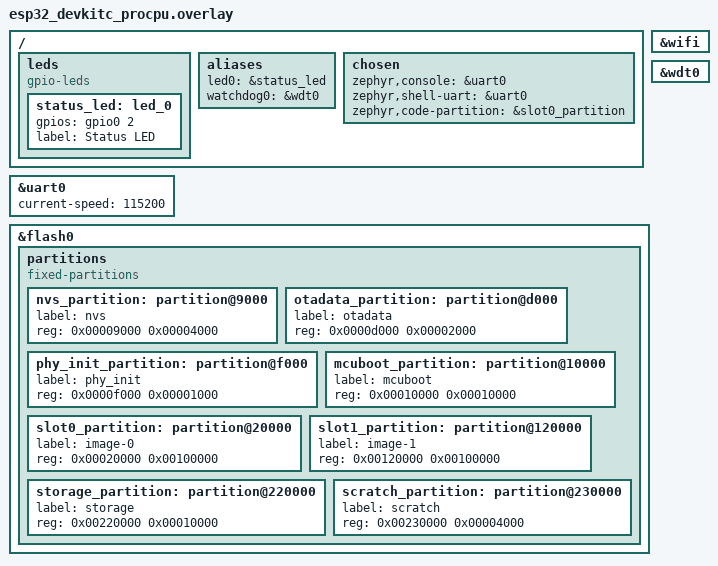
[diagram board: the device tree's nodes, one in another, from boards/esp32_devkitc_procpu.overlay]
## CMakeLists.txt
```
# SPDX-License-Identifier: Apache-2.0

cmake_minimum_required(VERSION 3.20.0)

find_package(Zephyr REQUIRED HINTS $ENV{ZEPHYR_BASE})
project(sample_with_mcuboot)

# Verify that this sample is built through sysbuild to ensure MCUboot is
# automatically included and that sample specific MCUboot configurations are
# used when building MCUboot.
test_sysbuild()

# Fügt Ihre C-Quelldateien zum "app"-Ziel hinzu.
target_sources(app PRIVATE
    src/main.c
    src/blinky.c
    src/wifi_mgmt.c
    src/ota_mgmt.c
    src/utils.c
)

#set(DTC_OVERLAY_FILE ${CMAKE_CURRENT_SOURCE_DIR}/boards/${BOARD}.overlay)

target_include_directories(app PRIVATE 
    include
)

if(CONFIG_RISCV AND CONFIG_SOC_SERIES_ESP32C3)
    target_compile_options(app PRIVATE -march=rv32ima)
    target_link_options(app PRIVATE -march=rv32ima)
endif()
```

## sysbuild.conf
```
SB_CONFIG_BOOTLOADER_MCUBOOT=y
SB_CONFIG_MCUBOOT_MODE_SWAP_USING_MOVE=y
SB_CONFIG_BOOT_SIGNATURE_TYPE_ECDSA_P256=y
SB_CONFIG_BOOT_SIGNATURE_KEY_FILE="C:/Users/SebastianR/Desktop/repos/zephyr-blinky-ota/zephyr-project/keys/ecdsa.pem"

#SB_CONFIG_BOOT_SIGNATURE_TYPE_ED25519=y
#SB_CONFIG_BOOT_SIGNATURE_KEY_FILE="C:/Users/SebastianR/Desktop/repos/zephyr-blinky-ota/zephyr-project/keys/ed25519.pem"

#SB_CONFIG_MCUBOOT_MODE_SWAP_SCRATCH=y
```

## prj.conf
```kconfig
# Empty file
# ======== Logging ========
CONFIG_LOG=y
#CONFIG_LOG_DEFAULT_LEVEL=3

# ======== Shell ========
CONFIG_SHELL=y
CONFIG_SHELL_BACKEND_SERIAL=y

# ======== Basic System and Hardware ========
CONFIG_GPIO=y
CONFIG_WATCHDOG=y
CONFIG_REBOOT=y
CONFIG_MAIN_STACK_SIZE=4096
CONFIG_SYSTEM_WORKQUEUE_STACK_SIZE=2048
CONFIG_HEAP_MEM_POOL_SIZE=65536

# ======== Networking =======
CONFIG_NETWORKING=y
CONFIG_NET_IPV4=y
CONFIG_NET_DHCPV4=y
CONFIG_NET_TCP=y
CONFIG_NET_SOCKETS=y
CONFIG_NET_MGMT=y
CONFIG_NET_MGMT_EVENT=y
CONFIG_NET_BUF_RX_COUNT=16
CONFIG_NET_BUF_TX_COUNT=16

# ======== WiFi ========
CONFIG_WIFI=y
CONFIG_WIFI_ESP32=y
CONFIG_NET_L2_WIFI_MGMT=y
CONFIG_HTTP_CLIENT=y

# ======== JSON Library ========
CONFIG_JSON_LIBRARY=y
# ======== MCUboot & OTA Support for the Application ========

CONFIG_IMG_MANAGER=y
CONFIG_MCUBOOT_IMG_MANAGER=y
CONFIG_IMG_BLOCK_BUF_SIZE=512
#CONFIG_MCUBOOT_SHELL=y # Erlaubt OTA-Befehle über die serielle Konsole
#CONFIG_MCUBOOT_IMGTOOL_SIGN_VERSION="1.0.14+2"

#CONFIG_BOOT_IMAGE_ACCESS_HOOKS=y
# ======== Flash Configuration ========
CONFIG_FLASH=y
CONFIG_FLASH_MAP=y
CONFIG_STREAM_FLASH=y
CONFIG_FLASH_PAGE_LAYOUT=y

# ======== ESP32 Specific Flash Settings ========
CONFIG_ESPTOOLPY_FLASHMODE_QIO=y
CONFIG_ESPTOOLPY_FLASHFREQ_80M=y
CONFIG_ESPTOOLPY_FLASHSIZE_4MB=y

CONFIG_BOOTLOADER_MCUBOOT=y
CONFIG_IMG_BLOCK_BUF_SIZE=1024

CONFIG_GPIO_ESP32=y
CONFIG_PINCTRL=y

# For debugging GPIO issues
CONFIG_GPIO_SHELL=y
CONFIG_DEVICE_SHELL=y
```

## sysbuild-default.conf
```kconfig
SB_CONFIG_BOOT_SIGNATURE_TYPE_ECDSA_P256=y
SB_CONFIG_BOOT_SIGNATURE_KEY_FILE="C:/Users/SebastianR/Desktop/repos/zephyr-blinky-ota/zephyr-project/keys/ecdsa.pem"
SB_CONFIG_BOOTLOADER_MCUBOOT=y
SB_CONFIG_MCUBOOT_MODE_SWAP_USING_MOVE=y
```

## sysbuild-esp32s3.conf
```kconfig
SB_CONFIG_BOOT_SIGNATURE_TYPE_ED25519=y
SB_CONFIG_BOOT_SIGNATURE_KEY_FILE="C:/Users/SebastianR/Desktop/repos/zephyr-blinky-ota/zephyr-project/keys/ed25519.pem"
```

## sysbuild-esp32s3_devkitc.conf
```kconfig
SB_CONFIG_BOOT_SIGNATURE_TYPE_ED25519=y
SB_CONFIG_BOOT_SIGNATURE_KEY_FILE="C:/Users/SebastianR/Desktop/repos/zephyr-blinky-ota/zephyr-project/keys/ed25519.pem"
SB_CONFIG_BOOTLOADER_MCUBOOT=y
SB_CONFIG_MCUBOOT_MODE_SWAP_USING_MOVE=y
```

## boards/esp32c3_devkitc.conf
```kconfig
CONFIG_REBOOT=y
```

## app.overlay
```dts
/*
 * Application-specific hardware configuration and flash layout.
 * The flash partition map here MUST match the one in the .yml file.
 */
/ {
    /* Board-specific hardware customization for your application */
    leds {
        compatible = "gpio-leds";
        status_led: led_0 {
            gpios = <&gpio0 2 GPIO_ACTIVE_HIGH>;
            label = "Status LED";
        };
    };

    aliases {
        led0 = &status_led;
        watchdog0 = &wdt0;
    };

    chosen {
        zephyr,console = &uart0;
        zephyr,shell-uart = &uart0;
        zephyr,code-partition = &slot0_partition; /* Tells Zephyr where the app runs */
    };
};

&uart0 {
    status = "okay";
    current-speed = <115200>;
};

&wifi {
    status = "okay";
};

&wdt0 {
    status = "okay";
};

/* Flash partitioning for OTA. MUST MATCH partitions.yml */
&flash0 {
    /delete-node/ partitions;
    partitions {
        compatible = "fixed-partitions";
        #address-cells = <1>;
        #size-cells = <1>;

        slot0_partition: partition@20000 {
            label = "slot0_partition";
            reg = <0x00020000 0x00100000>;
        };

        slot1_partition: partition@120000 {
            label = "slot1_partition";
            reg = <0x00120000 0x00100000>;
        };

        scratch_partition: partition@220000 {
            label = "scratch_partition";
            reg = <0x00220000 0x00040000>;
        };

        storage_partition: partition@260000 {
            label = "storage_partition";
            reg = <0x00260000 0x00008000>;
        };
    };
};
```

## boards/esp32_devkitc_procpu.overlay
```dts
/*
 * Application-specific hardware configuration and flash layout.
 * The flash partition map here MUST match the one in the .yml file.
 */

/ {
    /* Board-specific hardware customization for your application */
    leds {
        compatible = "gpio-leds";
        status_led: led_0 {
            gpios = <&gpio0 2 GPIO_ACTIVE_HIGH>;
            label = "Status LED";
        };
    };

    aliases {
        led0 = &status_led;
        watchdog0 = &wdt0;
    };

    chosen {
        zephyr,console = &uart0;
        zephyr,shell-uart = &uart0;
        zephyr,code-partition = &slot0_partition; /* Tells Zephyr where the app runs */
    };
};

&uart0 {
    status = "okay";
    current-speed = <115200>;
};

&wifi {
    status = "okay";
};

&wdt0 {
    status = "okay";
};


&flash0 {
    /delete-node/ partitions;
    partitions {
        compatible = "fixed-partitions";
        #address-cells = <1>;
        #size-cells = <1>;

        /* ESP32 Partition Table */
        nvs_partition: partition@9000 {
            label = "nvs";
            reg = <0x00009000 0x00004000>;
        };

        otadata_partition: partition@d000 {
            label = "otadata";
            reg = <0x0000d000 0x00002000>;
        };

        phy_init_partition: partition@f000 {
            label = "phy_init";
            reg = <0x0000f000 0x00001000>;
        };

        mcuboot_partition: partition@10000 {
            label = "mcuboot";
            reg = <0x00010000 0x00010000>;
        };

        slot0_partition: partition@20000 {
            label = "image-0";
            reg = <0x00020000 0x00100000>;
        };

        slot1_partition: partition@120000 {
            label = "image-1";
            reg = <0x00120000 0x00100000>;
        };

        storage_partition: partition@220000 {
            label = "storage";
            reg = <0x00220000 0x00010000>;
        };

        scratch_partition: partition@230000 {
            label = "scratch";
            reg = <0x00230000 0x00004000>;
        };
    };
};
```

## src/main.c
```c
#include "app_config.h"
#include "blinky.h"
#include "wifi_mgmt.h"
#include "ota_mgmt.h"
#include "utils.h"

#include <zephyr/kernel.h>
#include <zephyr/logging/log.h>
#include <zephyr/dfu/mcuboot.h>
#include <zephyr/linker/linker-defs.h>


LOG_MODULE_REGISTER(main, LOG_LEVEL_INF);

// Define a work item for the delayed confirmation
static void confirm_work_handler(struct k_work *work);
static K_WORK_DELAYABLE_DEFINE(confirm_work, confirm_work_handler);

static void confirm_work_handler(struct k_work *work)
{
    LOG_INF("Confirming running firmware as valid.");
    if (boot_write_img_confirmed() != 0) {
        LOG_ERR("Failed to confirm image! This may cause a revert on next boot.");
    } else {
        LOG_INF("Image confirmed successfully. The update is now permanent.");
        ota_check_for_update();
    }
}

/* OTA status callback */
static void ota_status_changed(ota_status_t status)
{
    switch (status) {
        case OTA_STATUS_CHECKING:
            LOG_INF("OTA: Checking for updates...");
            break;
        case OTA_STATUS_UPDATE_AVAILABLE:
            LOG_INF("OTA: Update available, preparing download");
            break;
        case OTA_STATUS_DOWNLOADING:
            blinky_set_interval(LED_FAST_BLINK_MS);
            LOG_INF("OTA: Downloading firmware update");
            break;
        case OTA_STATUS_DOWNLOAD_COMPLETE:
            LOG_INF("OTA: Download complete, preparing to apply");
            break;
        case OTA_STATUS_APPLYING:
            LOG_INF("OTA: Applying update, device will reboot");
            break;
        case OTA_STATUS_ERROR:
            blinky_set_interval(LED_ERROR_PATTERN);
            LOG_ERR("OTA: Error occurred, code: %d", ota_get_last_error());
            break;
        case OTA_STATUS_SLEEPING:
            blinky_set_interval(LED_SLOW_BLINK_MS);
            LOG_INF("OTA: Going to sleep");
            break;
        default:
            blinky_set_interval(LED_BLINK_INTERVAL_MS);
            break;
    }
}

int main(void)
{
    LOG_INF("====================================");
    LOG_INF("   ESP32 OTA Application Booting    ");
    LOG_INF("====================================");

    if (boot_is_img_confirmed() == 0) {
        LOG_WRN("Running new firmware in TEST mode.");
        LOG_WRN("Scheduling confirmation in 30 seconds.");
        k_work_schedule(&confirm_work, K_SECONDS(30));
    } else {
        LOG_INF("Running a confirmed image.");
    }
    LOG_DBG("Address of app %p\n", (void *)__rom_region_start);

    ota_register_status_callback(ota_status_changed);

    char current_ver[16];
    int rc = ota_get_running_firmware_version(current_ver, sizeof(current_ver));
    if (rc == 0) {
        LOG_INF("Current running version: %s", current_ver);
    } else {
        LOG_WRN("Something is wrong with the version getter");
    }
    
    bool ip_printed = false;

    LOG_INF("Main loop started. System is running.");
    while (1) {
        k_sleep(K_SECONDS(5));

        if(!ip_printed) {
            char ip_str[16];
            int result = wifi_get_ip_address_public(ip_str, sizeof(ip_str));
            if (result == 0) {
                LOG_INF("IP: %s", ip_str);
                ip_printed = true;
            } else {
                LOG_INF("No IP yet");
            }
        }
    }
    
    return 0;
}
```

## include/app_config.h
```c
#ifndef APP_CONFIG_H
#define APP_CONFIG_H

/* LED Configuration */
#define LED_BLINK_INTERVAL_MS 1000
#define LED_SLOW_BLINK_MS 2000
#define LED_FAST_BLINK_MS 100
#define LED_ERROR_PATTERN 250

/* WiFi Configuration */
#define WIFI_SSID " :)"
#define WIFI_PSK "Schaezler17"

/* OTA Server Configuration */
#define OTA_SERVER_HOST "172.27.48.159" //"192.168.2.86"  // Replace with your server IP
#define OTA_SERVER_PORT 8080
#define OTA_VERSION_URL "/api/version"
#define OTA_FIRMWARE_URL "/api/firmware"

/* OTA Update Configuration */
#define OTA_CHECK_INTERVAL_SEC 3600  // Check for updates every hour
#define OTA_MAX_DOWNLOAD_RETRIES 3
#define OTA_DOWNLOAD_TIMEOUT_MS 30000

#endif /* APP_CONFIG_H */
```

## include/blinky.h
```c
#ifndef BLINKY_H
#define BLINKY_H

#include <stdint.h>

#ifdef __cplusplus
extern "C" {
#endif

/**
 * @brief Set LED blink interval
 * 
 * @param interval_ms Blink interval in milliseconds
 */
void blinky_set_interval(uint32_t interval_ms);

/**
 * @brief Set LED state
 * 
 * @param state 0 for off, 1 for on
 */
void blinky_set_state(int state);

#ifdef __cplusplus
}
#endif

#endif /* BLINKY_H */
```

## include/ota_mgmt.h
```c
#ifndef OTA_MGMT_H
#define OTA_MGMT_H

#ifdef __cplusplus
extern "C" {
#endif

/* OTA update status codes */
typedef enum {
    OTA_STATUS_IDLE = 0,
    OTA_STATUS_CHECKING,
    OTA_STATUS_UPDATE_AVAILABLE,
    OTA_STATUS_DOWNLOADING,
    OTA_STATUS_DOWNLOAD_COMPLETE,
    OTA_STATUS_APPLYING,
    OTA_STATUS_ERROR,
    OTA_STATUS_SLEEPING,
} ota_status_t;

/* OTA error codes */
typedef enum {
    OTA_ERR_NONE = 0,
    OTA_ERR_SERVER_CONNECT,
    OTA_ERR_DOWNLOAD_FAILED,
    OTA_ERR_FLASH_INIT,
    OTA_ERR_FLASH_WRITE,
    OTA_ERR_APPLY_UPDATE,
    OTA_ERR_INVALID_IMAGE,
} ota_error_t;

/**
 * @brief Manually trigger an OTA update check
 * 
 * @return 0 if check was started, negative error code on failure
 */
int ota_check_for_update(void);

/**
 * @brief Get current OTA status
 * 
 * @return Current OTA status code
 */
ota_status_t ota_get_status(void);

/**
 * @brief Get last OTA error
 * 
 * @return Last error code
 */
ota_error_t ota_get_last_error(void);

/**
 * @brief Register callback for OTA status changes
 * 
 * @param callback Function to call when OTA status changes
 */
void ota_register_status_callback(void (*callback)(ota_status_t status));

#ifdef __cplusplus
}
#endif

#endif /* OTA_MGMT_H */
```

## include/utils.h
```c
#ifndef UTILS_H
#define UTILS_H

#include <stddef.h>

#ifdef __cplusplus
extern "C" {
#endif

/**
 * @brief Debug function to print image headers from both slots
 * 
 * This function reads and logs the MCUboot image headers from both
 * slot0 (currently running) and slot1 (OTA update) partitions.
 * Useful for debugging OTA update status and image information.
 */
void debug_image_headers(void);

/**
 * @brief Get the version of the currently running firmware.
 *
 * This function reads the image header from the primary (active) slot,
 * formats the semantic version into a string, and stores it in the
 * provided buffer.
 *
 * @param buf       A character buffer to store the version string.
 * @param buf_size  The size of the provided buffer.
 *
 * @return 0 on success.
 * @return -EIO if the image header could not be read.
 * @return -ENOMEM if the provided buffer is too small to hold the version string.
 * @return A negative error code from the underlying boot/flash functions on other failures.
 */
int ota_get_running_firmware_version(char *buf, size_t buf_size);

#ifdef __cplusplus
}
#endif

#endif /* UTILS_H */
```

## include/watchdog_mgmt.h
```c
#ifndef WATCHDOG_MANAGER_H
#define WATCHDOG_MANAGER_H

#include <zephyr/kernel.h>

/**
 * @brief Initializes the watchdog manager and the underlying hardware watchdog.
 *
 * This function should be called once at startup before any tasks
 * that need monitoring are started. It also starts a periodic timer
 * that checks the health of all registered tasks.
 *
 * @param check_interval The interval at which the manager checks task health.
 *                       Should be significantly shorter than the watchdog timeout.
 * @return 0 on success, or a negative error code on failure.
 */
int watchdog_manager_init(k_timeout_t check_interval);

/**
 * @brief Registers a task with the watchdog manager.
 *
 * Each critical task that needs to be monitored must register itself.
 * The manager returns a handle (ID) that the task must use to check in.
 *
 * @return A valid handle (>= 0) on success, or a negative error code if
 *         the manager is full or not initialized.
 */
int watchdog_manager_register_task(void);

/**
 * @brief Allows a registered task to "check in" or "pet" the manager.
 *
 * Tasks must call this periodically to signal that they are still alive
 * and functioning correctly.
 *
 * @param task_handle The handle received from watchdog_manager_register_task().
 */
void watchdog_manager_check_in(int task_handle);

/**
 * @brief Enables or disables watchdog monitoring for a specific task.
 *
 * When monitoring is disabled for a task, the manager will not expect
 * it to check in. This is useful for tasks that may be legitimately
 * idle or blocked for long periods (e.g., waiting for network).
 * The task MUST be re-enabled before it becomes active again.
 *
 * @param task_handle The handle of the task to modify.
 * @param enable      True to enable monitoring, false to disable.
 */
void watchdog_manager_enable_monitoring(int task_handle, bool enable);

/**
 * @brief Checks if monitoring is currently enabled for a task.
 *
 * @param task_handle The handle of the task.
 * @return True if the task is being monitored, false otherwise.
 */
bool watchdog_manager_is_monitoring_enabled(int task_handle);

#endif /* WATCHDOG_MANAGER_H */
```

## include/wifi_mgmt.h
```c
#ifndef WIFI_MGMT_H
#define WIFI_MGMT_H

#include <stdbool.h>
#include <stddef.h>

#ifdef __cplusplus
extern "C" {
#endif

/**
 * @brief Check if WiFi is connected
 * 
 * @return true if WiFi is connected, false otherwise
 */
bool wifi_is_connected(void);

/**
 * @brief Get current WiFi IP address as string
 * @param[out] ip_str Buffer for IP address string (min. 16 bytes)
 * @param[in] len Buffer size
 * @return 0 on success, negative error code on failure
 */
int wifi_get_ip_address_public(char *ip_str, size_t len);

#ifdef __cplusplus
}
#endif

#endif /* WIFI_MGMT_H */
```

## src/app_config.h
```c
#ifndef APP_CONFIG_H
#define APP_CONFIG_H

/* Application Configuration */
#define APP_NAME "ESP32_BLINKY_OTA"
#define APP_VERSION_MAJOR 1
#define APP_VERSION_MINOR 0
#define APP_VERSION_PATCH 12

/* LED Configuration */
#define LED_BLINK_INTERVAL_MS 1000
#define LED_FAST_BLINK_MS 100
#define LED_SLOW_BLINK_MS 2000
#define LED_ERROR_PATTERN 250  // Fast blink for errors

/* WiFi Configuration */
#define WIFI_SSID " :)"
#define WIFI_PSK "Schaezler17"

/* OTA Server Configuration */
#define OTA_SERVER_HOST "192.168.2.86"  // Replace with your server IP
#define OTA_SERVER_PORT 8080
#define OTA_VERSION_URL "/api/version"
#define OTA_FIRMWARE_URL "/api/firmware"

/* OTA Update Configuration */
#define OTA_CHECK_INTERVAL_SEC 3600  // Check for updates every hour
#define OTA_MAX_DOWNLOAD_RETRIES 3
#define OTA_DOWNLOAD_TIMEOUT_MS 30000

#endif /* APP_CONFIG_H */
```

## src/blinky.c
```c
#include "blinky.h"
#include "app_config.h"

#include <zephyr/kernel.h>
#include <zephyr/drivers/gpio.h>
#include <zephyr/init.h>
#include <zephyr/logging/log.h>


LOG_MODULE_REGISTER(blinky, LOG_LEVEL_INF);

#define LED0_NODE DT_ALIAS(led0)

static struct k_work_delayable blink_work;
static uint8_t led_state = 0;
static uint32_t blink_interval_ms = LED_BLINK_INTERVAL_MS;
static const struct gpio_dt_spec led = GPIO_DT_SPEC_GET(LED0_NODE, gpios);

// Forward declarations
static int blinky_init(void);
static void blink_work_handler(struct k_work *work);

// public functions
void blinky_set_interval(uint32_t interval_ms)
{
    if (interval_ms == 0) {
        interval_ms = LED_BLINK_INTERVAL_MS;
    }
    
    if (blink_interval_ms != interval_ms) {
        LOG_INF("Changing blink interval from %d ms to %d ms", blink_interval_ms, interval_ms);
        
        blink_interval_ms = interval_ms;
        
        /* Cancel current work and reschedule with new interval */
        k_work_cancel_delayable(&blink_work);
        k_work_schedule(&blink_work, K_MSEC(blink_interval_ms));
    }
}

void blinky_set_state(int state)
{
    if (state >= 0) {
        led_state = state ? 1 : 0;
        gpio_pin_set_dt(&led, led_state);
    }
}

// private static functions
static int blinky_init(void)
{
    if (!device_is_ready(led.port)) {
        LOG_ERR("LED device not ready");
        return -ENODEV;
    }

    int ret = gpio_pin_configure_dt(&led, GPIO_OUTPUT_ACTIVE);
    if (ret < 0) {
        LOG_ERR("Failed to configure LED GPIO: %d", ret);
        return ret;
    }

    k_work_init_delayable(&blink_work, blink_work_handler);
    k_work_schedule(&blink_work, K_MSEC(blink_interval_ms));

    LOG_INF("Blinky subsystem initialized - blinking every %d ms", blink_interval_ms);
    return 0;
}

static void blink_work_handler(struct k_work *work)
{
    ARG_UNUSED(work);

    gpio_pin_set_dt(&led, led_state);
    led_state ^= 1; // switch LED state
    k_work_schedule(&blink_work, K_MSEC(blink_interval_ms));
}

SYS_INIT(blinky_init, APPLICATION, CONFIG_APPLICATION_INIT_PRIORITY);
```

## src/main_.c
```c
#include <zephyr/kernel.h>
#include <zephyr/device.h>
#include <zephyr/devicetree.h>
#include <zephyr/drivers/flash.h>
#include <zephyr/storage/flash_map.h>
#include <zephyr/dfu/mcuboot.h>
#include <zephyr/logging/log.h>

LOG_MODULE_REGISTER(main, LOG_LEVEL_INF);

int main(void)
{
    LOG_INF("Starting Zephyr App with MCUboot support");
    
    // Image-Status überprüfen
    if (boot_is_img_confirmed()) {
        LOG_INF("Image is confirmed");
    } else {
        LOG_INF("Image is not confirmed, confirming now");
        boot_write_img_confirmed();
    }
    
    // Haupt-App-Logik hier
    while (1) {
        LOG_INF("App running...");
        k_sleep(K_SECONDS(5));
    }
    
    return 0;
}
```

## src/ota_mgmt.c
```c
#include "wifi_mgmt.h"
#include "app_config.h"
#include "ota_mgmt.h"
#include "blinky.h"
#include "utils.h"

#include <zephyr/kernel.h>
#include <zephyr/net/socket.h>
#include <zephyr/storage/flash_map.h>
#include <zephyr/dfu/mcuboot.h>
#include <zephyr/storage/stream_flash.h>
#include <zephyr/sys/reboot.h>
#include <zephyr/logging/log.h>
#include <zephyr/init.h>
#include <zephyr/net/http/client.h>
#include <zephyr/net/net_ip.h>
#include <zephyr/data/json.h>
#include <string.h>
#include <zephyr/devicetree.h>
#include <zephyr/dfu/flash_img.h>
#include <stdio.h>


LOG_MODULE_REGISTER(ota_mgmt, LOG_LEVEL_INF);

struct flash_img_context image_ctx;

/* OTA state variables */
static struct k_work_delayable ota_check_work;
static ota_status_t current_status = OTA_STATUS_IDLE;
static ota_error_t last_error = OTA_ERR_NONE;
static void (*status_callback)(ota_status_t) = NULL;

/* HTTP client context */
static struct http_request http_req;
static uint8_t http_recv_buf[1024];
static int64_t content_length = 0;
static size_t total_downloaded = 0;
static bool headers_complete = false;
static int retry_count = 0;
static int http_sock = -1;

struct version_info {
    const char *version;
    int size;
};

static struct json_obj_descr version_descr[] = {
    JSON_OBJ_DESCR_PRIM(struct version_info, version, JSON_TOK_STRING),
    JSON_OBJ_DESCR_PRIM(struct version_info, size, JSON_TOK_NUMBER),
};

// Forward declarations
static int ota_mgmt_init(void);
static void ota_check_work_handler(struct k_work *work);
static int check_for_update(void);
static int download_update(void);
static int apply_update(void);

static void update_status(ota_status_t new_status);
static void set_error(ota_error_t error);
static void ota_enter_backoff_state(void);

static int handle_http_headers(struct http_response *rsp);
static int handle_version_response(struct http_response *rsp);
static int handle_firmware_download(struct http_response *rsp, enum http_final_call final_data);
static int process_version_info(const char *json_data, size_t len);
static int write_firmware_chunk(const char *data, size_t len, bool is_final);
static int create_http_socket(const char *host, int port);

// Public functions
int ota_check_for_update(void)
{
    if (current_status == OTA_STATUS_SLEEPING) {
        LOG_INF("Waking ota manager up..");
        update_status(OTA_STATUS_IDLE);
    }
    if (current_status != OTA_STATUS_IDLE) {
        LOG_WRN("OTA operation already in progress");
        return -EBUSY;
    }
    
    return check_for_update();
}

ota_status_t ota_get_status(void)
{
    return current_status;
}

ota_error_t ota_get_last_error(void)
{
    return last_error;
}

void ota_register_status_callback(void (*callback)(ota_status_t status))
{
    status_callback = callback;
}

// private static functions
static int http_response_cb(struct http_response *rsp, enum http_final_call final_data, void *user_data)
{
    int ret = 0;
    if (!headers_complete && rsp->body_frag_len > 0) {
        ret = handle_http_headers(rsp);
        if (ret != 0) {
            return ret;
        }
    }

    if (headers_complete && rsp->body_frag_len > 0) {
        switch (current_status) {
            case OTA_STATUS_CHECKING:
                return handle_version_response(rsp);
                
            case OTA_STATUS_DOWNLOADING:
                return handle_firmware_download(rsp, final_data);
                
            default:
                LOG_WRN("Unexpected status in HTTP callback: %d", current_status);
                return 0;
        }
    }

    return 0;
}

static int handle_http_headers(struct http_response *rsp)
{
    if (rsp->http_status_code != 200) {
        LOG_ERR("HTTP request failed with status: %d %s", rsp->http_status_code, rsp->http_status);
        set_error(OTA_ERR_DOWNLOAD_FAILED);
        return -1;
    }
    
    headers_complete = true;
    content_length = rsp->content_length;
    LOG_INF("HTTP headers complete, content length: %lld", content_length);
    return 0;
}

static int handle_version_response(struct http_response *rsp)
{
    return process_version_info(rsp->body_frag_start, rsp->body_frag_len);
}

static int handle_firmware_download(struct http_response *rsp, enum http_final_call final_data)
{
    if (total_downloaded == 0) {
        LOG_INF("Flash initialized for firmware download");
    }
    
    return write_firmware_chunk(rsp->body_frag_start, rsp->body_frag_len, (final_data == HTTP_DATA_FINAL));
}

static int process_version_info(const char *json_data, size_t len)
{
    struct version_info version = {0};
    int ret;
    ret = json_obj_parse((char *)json_data, len, version_descr, ARRAY_SIZE(version_descr), &version);
    if (ret <= 0 || !version.version) {
        LOG_ERR("Failed to parse version info");
        set_error(OTA_ERR_SERVER_CONNECT);
        return -1;
    }
    
    LOG_INF("Server version: %s", version.version);

    char current_ver[16];
    ota_get_running_firmware_version(current_ver, sizeof(current_ver));
    
    if (strcmp(version.version, current_ver) != 0) {
        LOG_INF("New version available: %s (current: %s)", version.version, current_ver);
        update_status(OTA_STATUS_UPDATE_AVAILABLE);
        k_work_schedule(&ota_check_work, K_SECONDS(5));
    } else {
        LOG_INF("Already running latest version. Checking again later.");
        ota_enter_backoff_state();
    }
    
    return 0;
}

static int write_firmware_chunk(const char *data, size_t len, bool is_final)
{
    int ret;
    
    ret = flash_img_buffered_write(&image_ctx, data, len, is_final);
    if (ret < 0) {
        LOG_ERR("Flash write error: %d", ret);
        set_error(OTA_ERR_FLASH_WRITE);
        return ret;
    }
    
    total_downloaded += len;

    if (is_final) {
        LOG_INF("Firmware download complete: %zu bytes", total_downloaded);
    }
    
    return 0;
}

static int create_http_socket(const char *host, int port)
{
    struct zsock_addrinfo hints, *result;
    int sock;
    int ret;
    
    sock = zsock_socket(AF_INET, SOCK_STREAM, IPPROTO_TCP);
    if (sock < 0) {
        LOG_ERR("Failed to create socket: %d", errno);
        return -1;
    }
    
    /* Set socket timeout */
    struct zsock_timeval timeout = {
        .tv_sec = 30,
        .tv_usec = 0,
    };
    
    zsock_setsockopt(sock, SOL_SOCKET, SO_RCVTIMEO, &timeout, sizeof(timeout));
    zsock_setsockopt(sock, SOL_SOCKET, SO_SNDTIMEO, &timeout, sizeof(timeout));
    
    /* Setup address resolution */
    memset(&hints, 0, sizeof(hints));
    hints.ai_family = AF_INET;
    hints.ai_socktype = SOCK_STREAM;
    
    char port_str[8];
    snprintf(port_str, sizeof(port_str), "%d", port);
    
    ret = zsock_getaddrinfo(host, port_str, &hints, &result);
    if (ret != 0) {
        LOG_ERR("Failed to resolve hostname %s: %d", host, ret);
        zsock_close(sock);
        return -1;
    }
    
    ret = zsock_connect(sock, result->ai_addr, result->ai_addrlen);
    zsock_freeaddrinfo(result);
    
    if (ret < 0) {
        LOG_ERR("Failed to connect to %s:%d: %d", host, port, errno);
        zsock_close(sock);
        return -1;
    }
    
    LOG_INF("Connected to %s:%d", host, port);
    return sock;
}

static void ota_enter_backoff_state(void) {
    set_error(OTA_ERR_NONE);
    update_status(OTA_STATUS_SLEEPING);
    LOG_WRN("Entering sleeping state.");
    k_work_schedule(&ota_check_work, K_SECONDS(OTA_CHECK_INTERVAL_SEC));
}

static void update_status(ota_status_t new_status)
{
    if (current_status != new_status) {
        current_status = new_status;

        if (status_callback != NULL) {
            status_callback(new_status);
        }
    }
}

static void set_error(ota_error_t error)
{
    last_error = error;
    update_status(OTA_STATUS_ERROR);
}

static int check_for_update(void)
{
    if (!wifi_is_connected()) {
        LOG_WRN("WiFi not connected (yet), skipping update check");
        return -ENOTCONN;
    }
    
    update_status(OTA_STATUS_CHECKING);
    
    /* try to create socket connection */
    http_sock = create_http_socket(OTA_SERVER_HOST, OTA_SERVER_PORT);
    if (http_sock < 0) {
        LOG_ERR("Server connection failed");
        return http_sock;
    }
    
    /* Setup HTTP request for version check */
    memset(&http_req, 0, sizeof(http_req));
    
    http_req.method = HTTP_GET;
    http_req.url = OTA_VERSION_URL;
    http_req.host = OTA_SERVER_HOST;
    http_req.protocol = "HTTP/1.1";
    http_req.response = http_response_cb;
    http_req.recv_buf = http_recv_buf;
    http_req.recv_buf_len = sizeof(http_recv_buf);
    
    headers_complete = false;
    
    LOG_INF("Checking for updates at http://%s:%d%s", OTA_SERVER_HOST, OTA_SERVER_PORT, OTA_VERSION_URL);
    int ret = http_client_req(http_sock, &http_req, 5000, NULL); //blocks until done
    
    /* Close socket */
    zsock_close(http_sock);
    http_sock = -1;
    
    /* in case something went wrong */
    if (ret < 0) {
        LOG_ERR("HTTP Request returned an error.");
    }
    
    return ret;
}

static int download_update(void)
{
    LOG_INF("Trying to download firmware, preparing flash area");

    if (!wifi_is_connected()) {
        LOG_WRN("WiFi not connected, cannot download update.");
        return -ENOTCONN;
    }

    const struct flash_area *fa;
    int ret;

    LOG_INF("Explicitly erasing slot1 before download...");
    ret = flash_area_open(DT_FIXED_PARTITION_ID(DT_NODELABEL(slot1_partition)), &fa);
    if (ret != 0) {
        LOG_ERR("Failed to open slot1 for erase: %d", ret);
        set_error(OTA_ERR_FLASH_INIT);
        return ret;
    }
    ret = flash_area_erase(fa, 0, fa->fa_size); // TODO: maybe remove -> deleting the whole flash area
    flash_area_close(fa);

    if (ret != 0) {
        LOG_ERR("Failed to erase slot1: %d", ret);
        set_error(OTA_ERR_FLASH_INIT);
        return ret;
    }
    LOG_INF("Slot1 cleared successfully.");
    ret = flash_img_init_id(&image_ctx, DT_FIXED_PARTITION_ID(DT_NODELABEL(slot1_partition)));
    LOG_INF("area ID of slot1: %d", DT_FIXED_PARTITION_ID(DT_NODELABEL(slot1_partition)));

    if (ret != 0) {
        LOG_ERR("Failed to initialize flash context: %d", ret);
        set_error(OTA_ERR_FLASH_INIT);
        return ret;
    }

    uint8_t area_id = flash_img_get_upload_slot();
    LOG_INF("Flash image using area ID: %d", area_id);
    
    update_status(OTA_STATUS_DOWNLOADING);
    http_sock = create_http_socket(OTA_SERVER_HOST, OTA_SERVER_PORT);
    if (http_sock < 0) {
        set_error(OTA_ERR_SERVER_CONNECT);
        LOG_ERR("Server connection failed.");
        return -ECONNREFUSED;
    }
    /* Setup HTTP request for firmware download */
    memset(&http_req, 0, sizeof(http_req));

    http_req.method = HTTP_GET;
    http_req.url = OTA_FIRMWARE_URL;
    http_req.host = OTA_SERVER_HOST;
    http_req.protocol = "HTTP/1.1";
    http_req.response = http_response_cb;
    http_req.recv_buf = http_recv_buf;
    http_req.recv_buf_len = sizeof(http_recv_buf);
    
    headers_complete = false;
    total_downloaded = 0; 

    LOG_INF("Downloading firmware from http://%s:%d%s", OTA_SERVER_HOST, OTA_SERVER_PORT, OTA_FIRMWARE_URL);

    ret = http_client_req(http_sock, &http_req, OTA_DOWNLOAD_TIMEOUT_MS, NULL); // blocks until done
    zsock_close(http_sock);
    http_sock = -1;
    
    if (ret < 0) {
        LOG_ERR("Failed to download firmware: %d", ret);
        set_error(OTA_ERR_DOWNLOAD_FAILED);

        if (++retry_count < OTA_MAX_DOWNLOAD_RETRIES) {
            LOG_INF("Retrying download (%d/%d) in 5 seconds...", retry_count + 1, OTA_MAX_DOWNLOAD_RETRIES);
            k_work_schedule(&ota_check_work, K_SECONDS(5));
        } else {
            LOG_ERR("Max retry attempts reached, giving up");
            retry_count = 0;
            update_status(OTA_STATUS_IDLE);
            return -1;
        }
    } else {
        LOG_INF("Firmware download successful.");
        update_status(OTA_STATUS_DOWNLOAD_COMPLETE);
        k_work_schedule(&ota_check_work, K_MSEC(100));
        retry_count = 0;
    }
    
    return ret;
}

static int apply_update(void)
{
    update_status(OTA_STATUS_APPLYING);
    int swap_type = mcuboot_swap_type();
    LOG_INF("Current swap type: %d", swap_type);

    debug_image_headers(); // this should print an overview of the images in slot0 and slot1

    int ret = boot_request_upgrade(BOOT_UPGRADE_TEST);
    if (ret != 0) {
        LOG_ERR("Failed to request upgrade: %d", ret);
        set_error(OTA_ERR_APPLY_UPDATE);
        return ret;
    }
    
    LOG_INF("Update ready - rebooting in 3 seconds");
    k_sleep(K_SECONDS(3));
    sys_reboot(SYS_REBOOT_WARM); //SYS_REBOOT_COLD -> no change because the signal bytes are stored anyways
    
    return 0;
}

static void ota_check_work_handler(struct k_work *work)
{
    ARG_UNUSED(work);
    int ret = 0;

    switch (current_status) {
        case OTA_STATUS_IDLE:
            ret = check_for_update();
            break;
            
        case OTA_STATUS_UPDATE_AVAILABLE:
            ret = download_update();
            break;
            
        case OTA_STATUS_DOWNLOAD_COMPLETE:
            ret = apply_update();
            break;
        case OTA_STATUS_SLEEPING:
            update_status(OTA_STATUS_IDLE);
            ret = check_for_update();
            break;
        default:
            break;
    }

    LOG_ERR("check for error in work handler: %d", ret);
    if(ret < 0) {
        ota_enter_backoff_state();
    }
}

static int ota_mgmt_init(void)
{
    k_work_init_delayable(&ota_check_work, ota_check_work_handler);

    if (boot_is_img_confirmed()) {
        LOG_INF("Scheduling initial OTA check in 30 seconds.");
        k_work_schedule(&ota_check_work, K_SECONDS(30));
    }

    LOG_INF("OTA management subsystem initialized");
    return 0;
}

/* Auto-initialize at APPLICATION level */
SYS_INIT(ota_mgmt_init, APPLICATION, CONFIG_APPLICATION_INIT_PRIORITY);
```

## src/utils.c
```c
#include "utils.h"

#include <stddef.h>                     // size_t
#include <stdio.h>                      // snprintf
#include <zephyr/devicetree.h>          // DT_FIXED_PARTITION_ID, DT_NODELABEL
#include <zephyr/dfu/mcuboot.h>         // mcuboot_img_header, boot_* functions
#include <zephyr/logging/log.h>         // LOG_* macros
#include <zephyr/storage/flash_map.h>   // flash_area_* functions


LOG_MODULE_REGISTER(utils, LOG_LEVEL_INF);

void debug_image_headers(void)
{
    //please ignore the duplicate code for slot0 and slot1 :)
    LOG_DBG("=== Image Header Debug ===");
    
    struct mcuboot_img_header header;
    int ret;
    
    // check Slot0
    ret = boot_read_bank_header(DT_FIXED_PARTITION_ID(DT_NODELABEL(slot0_partition)), &header, sizeof(header));
    if (ret == 0) {
        LOG_DBG("Slot0 - Image size: %u", header.h.v1.image_size);
        LOG_DBG("Slot0 - Version: %u.%u.%u+%u", 
               header.h.v1.sem_ver.major,
               header.h.v1.sem_ver.minor,
               header.h.v1.sem_ver.revision,
               header.h.v1.sem_ver.build_num);
    } else {
        LOG_DBG("Failed to read slot0 header: %d", ret);
        const struct flash_area *fa;
        if (flash_area_open(DT_FIXED_PARTITION_ID(DT_NODELABEL(slot0_partition)), &fa) == 0) {
            uint32_t magic;
            flash_area_read(fa, 0, &magic, sizeof(magic));
            LOG_DBG("Slot0 raw magic: 0x%08x", magic);
            flash_area_close(fa);
        }
    }
    
    // check Slot1
    ret = boot_read_bank_header(DT_FIXED_PARTITION_ID(DT_NODELABEL(slot1_partition)), &header, sizeof(header));
    if (ret == 0) {
        LOG_DBG("Slot1 - Image size: %u", header.h.v1.image_size);
        LOG_DBG("Slot1 - Version: %u.%u.%u+%u", 
               header.h.v1.sem_ver.major,
               header.h.v1.sem_ver.minor,
               header.h.v1.sem_ver.revision,
               header.h.v1.sem_ver.build_num);
    } else {
        LOG_DBG("Failed to read slot1 header: %d", ret);
        const struct flash_area *fa;
        if (flash_area_open(DT_FIXED_PARTITION_ID(DT_NODELABEL(slot1_partition)), &fa) == 0) {
            uint32_t magic;
            flash_area_read(fa, 0, &magic, sizeof(magic));
            LOG_DBG("Slot1 raw magic: 0x%08x", magic);
            flash_area_close(fa);
        }
    }
}

int ota_get_running_firmware_version(char *buf, size_t buf_size)
{
    struct mcuboot_img_header header;
    int rc;

    // TODO: boot_fetch_active_slot() not working on esp32_s3 boot_fetch_active_slot 
    uint8_t active_slot_id = boot_fetch_active_slot(); 
    uint8_t slot_id = DT_FIXED_PARTITION_ID(DT_NODELABEL(slot0_partition));
    LOG_INF("Active Slot ID: %u, hard coded Slot ID: %u", active_slot_id, slot_id);
    rc = boot_read_bank_header(slot_id, &header, sizeof(header));
    if (rc != 0) {
        LOG_ERR("Failed to read running image header from slot %u. Error: %d",
                active_slot_id, rc);
        return rc;
    }
    rc = snprintf(buf, buf_size, "%u.%u.%u",
                  header.h.v1.sem_ver.major,
                  header.h.v1.sem_ver.minor,
                  header.h.v1.sem_ver.revision);

    if (rc < 0 || rc >= buf_size) {
        LOG_ERR("Buffer too small for version string. Required: %d, available: %zu",
                rc, buf_size);
        return -ENOMEM;
    }

    return 0;
}
```

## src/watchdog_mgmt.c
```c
#include "watchdog_manager.h"
#include <zephyr/drivers/watchdog.h>
#include <zephyr/logging/log.h>
#include <stdatomic.h>

LOG_MODULE_REGISTER(wdt_mgr, LOG_LEVEL_INF);

#define MAX_MONITORED_TASKS 4 // Maximale Anzahl an Tasks, die überwacht werden können

static const struct device *wdt_dev;
static int wdt_channel_id;

static atomic_uint g_task_check_ins[MAX_MONITORED_TASKS];
static atomic_int g_registered_tasks_count = ATOMIC_VAR_INIT(0);

static struct k_timer wdt_mgr_timer;

/*
 * This is the core logic. It's a timer callback that runs periodically.
 */
static void watchdog_manager_check_tasks(struct k_timer *timer)
{
    bool all_tasks_ok = true;
    int task_count = atomic_load(&g_registered_tasks_count);

    for (int i = 0; i < task_count; i++) {
        // Exchange the flag: check if it was 1, and set it back to 0 atomically.
        if (atomic_exchange(&g_task_check_ins[i], 0) == 0) {
            // This task did NOT check in since the last cycle.
            LOG_ERR("Watchdog: Task with handle %d failed to check in!", i);
            all_tasks_ok = false;
        }
    }

    if (all_tasks_ok) {
        if (wdt_dev) {
            wdt_feed(wdt_dev, wdt_channel_id);
            LOG_DBG("All %d tasks checked in. Watchdog fed.", task_count);
        }
    } else {
        LOG_WRN("Watchdog not fed due to missing check-in. System will reset soon.");
        // We do nothing, letting the hardware watchdog time out.
    }
}

int watchdog_manager_init(k_timeout_t check_interval)
{
    wdt_dev = DEVICE_DT_GET(DT_ALIAS(watchdog0));
    if (!device_is_ready(wdt_dev)) {
        LOG_ERR("Hardware watchdog device not found or not ready.");
        return -ENODEV;
    }

    struct wdt_timeout_cfg wdt_config = {
        .window.min = 0,
        .window.max = 10000, // 10-Sekunden-Hardware-Timeout
        .callback = NULL,
        .flags = WDT_FLAG_RESET_SOC,
    };
    wdt_channel_id = wdt_install_timeout(wdt_dev, &wdt_config);
    if (wdt_channel_id < 0) {
        LOG_ERR("Failed to install watchdog timeout: %d", wdt_channel_id);
        return wdt_channel_id;
    }
    wdt_setup(wdt_dev, WDT_OPT_PAUSE_HALTED_BY_DBG);

    // Initialisiere und starte unseren periodischen Software-Check-Timer
    k_timer_init(&wdt_mgr_timer, watchdog_manager_check_tasks, NULL);
    k_timer_start(&wdt_mgr_timer, check_interval, check_interval);

    LOG_INF("Watchdog Manager initialized. Check interval: %u ms, HW timeout: %u ms",
            check_interval.ticks, wdt_config.window.max);

    return 0;
}

int watchdog_manager_register_task(void)
{
    int handle = atomic_fetch_add(&g_registered_tasks_count, 1);
    if (handle >= MAX_MONITORED_TASKS) {
        atomic_store(&g_registered_tasks_count, MAX_MONITORED_TASKS); // Korrigiere den Zähler
        LOG_ERR("Cannot register more tasks. Limit of %d reached.", MAX_MONITORED_TASKS);
        return -ENOMEM;
    }

    // Initialisiere das Check-in-Flag auf 0. Der Task muss sofort einchecken.
    atomic_store(&g_task_check_ins[handle], 0);
    LOG_INF("Task registered with handle %d", handle);
    return handle;
}

void watchdog_manager_check_in(int task_handle)
{
    if (task_handle < 0 || task_handle >= MAX_MONITORED_TASKS) {
        return; // Ungültiges Handle
    }
    atomic_store(&g_task_check_ins[task_handle], 1);
}
```
